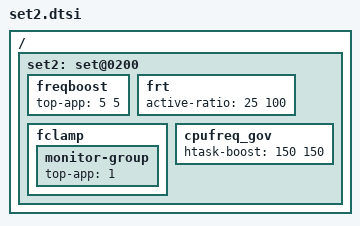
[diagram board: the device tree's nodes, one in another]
/ {
	/* performance mode - default */
	set2: set@0200 {
		/* Boosting margin applied to frequency selection */
		freqboost {			/* LIT BIG */
			top-app			= <  5   5>;
		};

		frt {	   	     		/* LIT BIG */
			active-ratio		= < 25 100>;
		};

		fclamp {
			monitor-group {
				top-app         = <1>;
			};
		};

		cpufreq_gov {
				/* LIT BIG */
			htask-boost = < 150 150 >;
		};
	};
};
